VERSION "DNNBNNNYNNNNNNNNNNNNNNNNNNYYYNNNNNNNNNNNNN/4/%%%/4/'%**4NNN///"

NS_ :

BS_:

BU_: BodyControl MotorControl Dashboard LightControl

BO_ 304 MsgWindowLeft: 8 Dashboard
 SG_ SigWindowLeftUp : 1|1@1+ (1,0) [0|0] ""  BodyControl
 SG_ SigWindowLeftDown : 0|1@1+ (1,0) [0|0] ""  BodyControl

BO_ 297 MsgWiperCmd: 8 Dashboard
 SG_ SigWiperOnOff : 0|1@1+ (1,0) [0|0] ""  BodyControl

BO_ 296 MsgLightCmd: 1 Dashboard
 SG_ SigLightOnOff : 0|1@1+ (1,0) [0|1] ""  LightControl

BO_ 294 MsgAlarmCmd: 1 Dashboard
 SG_ SigAlarmOnOff : 0|1@1+ (1,0) [0|1] ""  LightControl

BO_ 295 MsgBlinkCmd: 2 Dashboard
 SG_ SigBlinkRightCmd : 8|1@1+ (1,0) [0|1] ""  LightControl
 SG_ SigBlinkLeftCmd : 0|1@1+ (1,0) [0|1] ""  LightControl

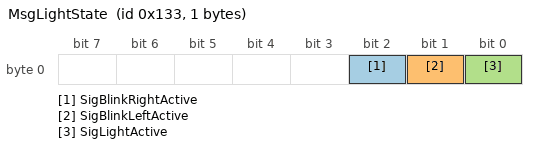
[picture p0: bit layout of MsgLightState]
BO_ 307 MsgLightState: 1 LightControl
 SG_ SigBlinkRightActive : 2|1@1+ (1,0) [0|1] "" Vector__XXX
 SG_ SigBlinkLeftActive : 1|1@1+ (1,0) [0|1] "" Vector__XXX
 SG_ SigLightActive : 0|1@1+ (1,0) [0|1] ""  Dashboard

BO_ 293 MsgBrakeState: 1 MotorControl
 SG_ SigBrakeActive : 0|1@1+ (1,0) [0|1] ""  Dashboard

BO_ 291 MsgBrakeCmd: 1 Dashboard
 SG_ SigBrakeOnOff : 0|1@1+ (1,0) [0|1] ""  MotorControl

BO_ 290 MsgMotorCmd: 3 Dashboard
 SG_ SigAcceleratorPosition : 0|16@1+ (1,0) [0|65535] "rpm"  MotorControl
 SG_ SigEngineOnOff : 16|1@1+ (1,0) [0|1] ""  MotorControl

BO_ 292 MsgMotorState: 3 MotorControl
 SG_ SigEngineSpeed : 0|16@1+ (1,0) [0|3500] "rpm"  Dashboard
 SG_ SigEngineActive : 16|1@1+ (1,0) [0|1] ""  LightControl,BodyControl,Dashboard

EV_ EnvWindowLeftPosition: 0 [0|16] "" 0 1 DUMMY_NODE_VECTOR0  BodyControl;

EV_ EnvWiperPosition: 0 [0|512] "" 0 2 DUMMY_NODE_VECTOR0  BodyControl;

EV_ EnvWindowLeftUp: 0 [0|1] "" 0 3 DUMMY_NODE_VECTOR0  Dashboard;

EV_ EnvWindowLeftDown: 0 [0|1] "" 0 4 DUMMY_NODE_VECTOR0  Dashboard;

EV_ EnvBlinkRightLED: 0 [0|1] "" 0 5 DUMMY_NODE_VECTOR0  Dashboard;

EV_ EnvBlinkLeftLED: 0 [0|1] "" 0 6 DUMMY_NODE_VECTOR0  Dashboard;

EV_ EnvLightLED: 0 [0|1] "" 0 7 DUMMY_NODE_VECTOR0  Dashboard;

EV_ EnvParkLight: 0 [0|1] "" 0 8 DUMMY_NODE_VECTOR0  LightControl;

EV_ EnvHeadAndTurnLightRight: 0 [0|9] "" 0 9 DUMMY_NODE_VECTOR0  LightControl;

EV_ EnvHeadAndTurnLightLeft: 0 [0|9] "" 0 10 DUMMY_NODE_VECTOR0  LightControl;

EV_ EnvBrakeSwitch: 0 [0|1] "" 0 11 DUMMY_NODE_VECTOR0  Dashboard;

EV_ EnvIgnitionSwitch: 0 [0|1] "" 0 12 DUMMY_NODE_VECTOR0  Dashboard;

EV_ EnvAlarmButton: 0 [0|1] "" 0 13 DUMMY_NODE_VECTOR0  Dashboard;

EV_ EnvLightButton: 0 [0|1] "" 0 14 DUMMY_NODE_VECTOR0  Dashboard;

EV_ EnvWiperButton: 0 [0|1] "" 0 15 DUMMY_NODE_VECTOR0  Dashboard;

EV_ EnvBlinkRightButton: 0 [0|1] "" 0 16 DUMMY_NODE_VECTOR0  Dashboard;

EV_ EnvBlinkLeftButton: 0 [0|1] "" 0 17 DUMMY_NODE_VECTOR0  Dashboard;

EV_ EnvAcceleratorPedal: 0 [0|3500] "" 750 18 DUMMY_NODE_VECTOR2  Dashboard;

BA_DEF_ BU_  "ILUsed" ENUM  "Yes","No";
BA_DEF_ SG_  "GenSigStartValue" FLOAT 0 100000000000;
BA_DEF_ SG_  "GenSigSendType" ENUM  "Cyclic","OnWrite","OnWriteWithRepetition","OnChange","OnChangeWithRepetition","IfActive","IfActiveWithRepetition";
BA_DEF_ BO_  "GenMsgDelayTime" INT 1 1000;
BA_DEF_ BO_  "GenMsgCycleTime" INT 2 50000;
BA_DEF_ BO_  "GenMsgSendType" ENUM  "Cyclic","not_used","not_used","not_used","not_used","Cyclic","not_used","IfActive";
BA_DEF_ BO_  "GenMsgCycleTimeFast" INT 2 100000;
BA_DEF_ BO_  "GenMsgILSupport" ENUM  "No","Yes";
BA_DEF_ BU_  "NodeLayerModules" STRING ;
BA_DEF_DEF_  "ILUsed" "Yes";
BA_DEF_DEF_  "GenSigStartValue" 0;
BA_DEF_DEF_  "GenSigSendType" "Cyclic";
BA_DEF_DEF_  "GenMsgDelayTime" 1;
BA_DEF_DEF_  "GenMsgCycleTime" 2;
BA_DEF_DEF_  "GenMsgSendType" "not_used";
BA_DEF_DEF_  "GenMsgCycleTimeFast" 100;
BA_DEF_DEF_  "GenMsgILSupport" "Yes";
BA_DEF_DEF_  "NodeLayerModules" "CANoeILNLVector.dll";
BA_ "GenMsgCycleTime" BO_ 290 100;
BA_ "GenMsgSendType" BO_ 290 0;
BA_ "GenMsgCycleTimeFast" BO_ 292 50;
BA_ "GenMsgCycleTime" BO_ 292 50;
BA_ "GenMsgSendType" BO_ 292 0;
BA_ "GenSigSendType" SG_ 304 SigWindowLeftUp 1;
BA_ "GenSigSendType" SG_ 304 SigWindowLeftDown 1;
BA_ "GenSigSendType" SG_ 297 SigWiperOnOff 3;
BA_ "GenSigSendType" SG_ 296 SigLightOnOff 3;
BA_ "GenSigSendType" SG_ 294 SigAlarmOnOff 3;
BA_ "GenSigSendType" SG_ 295 SigBlinkRightCmd 3;
BA_ "GenSigSendType" SG_ 295 SigBlinkLeftCmd 3;
BA_ "GenSigSendType" SG_ 307 SigBlinkRightActive 3;
BA_ "GenSigSendType" SG_ 307 SigBlinkLeftActive 3;
BA_ "GenSigSendType" SG_ 307 SigLightActive 3;
BA_ "GenSigSendType" SG_ 293 SigBrakeActive 3;
BA_ "GenSigSendType" SG_ 291 SigBrakeOnOff 3;
